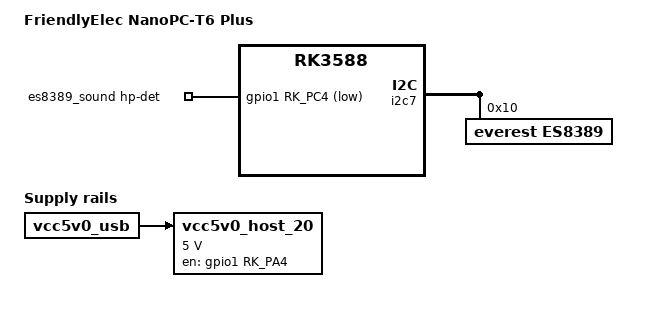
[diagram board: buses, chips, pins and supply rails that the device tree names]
// SPDX-License-Identifier: (GPL-2.0+ OR MIT)
/*
 * Copyright (c) 2025 FriendlyElec Computer Tech. Co., Ltd.
 * (http://www.friendlyelec.com)
 */

/dts-v1/;
#include "rk3588-nanopi6-rev01.dts"

/delete-node/ &rt5616;
/delete-node/ &rt5616_sound;

/ {
	model = "FriendlyElec NanoPC-T6 Plus";
	compatible = "friendlyelec,nanopc-t6", "rockchip,rk3588";

	es8389_sound: es8389-sound {
		status = "okay";
		compatible = "rockchip,multicodecs-card";
		pinctrl-names = "default";
		pinctrl-0 = <&hp_det>;
		rockchip,card-name = "rockchip-es8389";
		hp-det-gpio = <&gpio1 RK_PC4 GPIO_ACTIVE_LOW>;
		rockchip,pre-power-on-delay-ms = <30>;
		rockchip,post-power-down-delay-ms = <40>;
		rockchip,format = "i2s";
		rockchip,mclk-fs = <256>;
		rockchip,cpu = <&i2s0_8ch>;
		rockchip,codec = <&es8389>;
		rockchip,audio-routing =
			"Headphone", "HPOL",
			"Headphone", "HPOR",
			"Headphone", "Headphone Power",
			"Headphone", "Headphone Power",
			"INPUT1", "Main Mic",
			"INPUT2", "Main Mic";
	};

	vcc5v0_host_20: vcc5v0-host-20 {
		compatible = "regulator-fixed";
		enable-active-high;
		gpio = <&gpio1 RK_PA4 GPIO_ACTIVE_HIGH>;
		pinctrl-names = "default";
		pinctrl-0 = <&vcc5v0_host20_en>;
		regulator-name = "vcc5v0_host_20";
		regulator-min-microvolt = <5000000>;
		regulator-max-microvolt = <5000000>;
		vin-supply = <&vcc5v0_usb>;
	};
};

&mach {
	hwrev = <0x0b>;
	model = "NanoPC-T6 Plus";
};

&i2c7 {
	es8389: es8389@10 {
		status = "okay";
		#sound-dai-cells = <0>;
		compatible = "everest,es8389";
		reg = <0x10>;
		clocks = <&mclkout_i2s0>;
		clock-names = "mclk";
		assigned-clocks = <&mclkout_i2s0>;
		assigned-clock-rates = <12288000>;
		pinctrl-names = "default";
		pinctrl-0 = <&i2s0_mclk>;
	};
};

&u2phy3_host {
	phy-supply = <&vcc5v0_host_20>;
};
